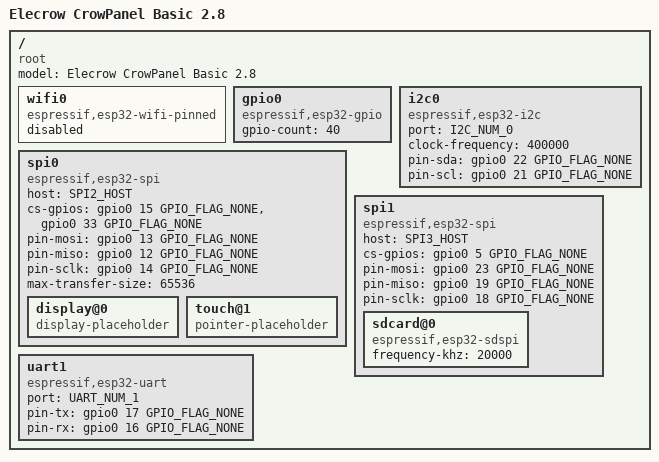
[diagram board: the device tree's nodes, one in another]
/dts-v1/;

#include <tactility/bindings/root.h>
#include <tactility/bindings/esp32_wifi_pinned.h>
#include <tactility/bindings/esp32_gpio.h>
#include <tactility/bindings/esp32_i2c.h>
#include <tactility/bindings/esp32_spi.h>
#include <tactility/bindings/esp32_uart.h>
#include <tactility/bindings/esp32_sdspi.h>
#include <tactility/bindings/display_placeholder.h>
#include <tactility/bindings/pointer_placeholder.h>

/ {
	compatible = "root";
	model = "Elecrow CrowPanel Basic 2.8";

	wifi0 {
		compatible = "espressif,esp32-wifi-pinned";
		status = "disabled";
	};

	gpio0 {
		compatible = "espressif,esp32-gpio";
		gpio-count = <40>;
	};

	i2c0 {
		compatible = "espressif,esp32-i2c";
		port = <I2C_NUM_0>;
		clock-frequency = <400000>;
		pin-sda = <&gpio0 22 GPIO_FLAG_NONE>;
		pin-scl = <&gpio0 21 GPIO_FLAG_NONE>;
	};

	spi0 {
		compatible = "espressif,esp32-spi";
		host = <SPI2_HOST>;
		cs-gpios = <&gpio0 15 GPIO_FLAG_NONE>, // Display
		            <&gpio0 33 GPIO_FLAG_NONE>; // Touch
		pin-mosi = <&gpio0 13 GPIO_FLAG_NONE>;
		pin-miso = <&gpio0 12 GPIO_FLAG_NONE>;
		pin-sclk = <&gpio0 14 GPIO_FLAG_NONE>;
		max-transfer-size = <65536>;
	
		display@0 {
			compatible = "display-placeholder";
		};

		touch@1 {
			compatible = "pointer-placeholder";
		};
	};

	spi1 {
		compatible = "espressif,esp32-spi";
		host = <SPI3_HOST>;
		cs-gpios = <&gpio0 5 GPIO_FLAG_NONE>;
		pin-mosi = <&gpio0 23 GPIO_FLAG_NONE>;
		pin-miso = <&gpio0 19 GPIO_FLAG_NONE>;
		pin-sclk = <&gpio0 18 GPIO_FLAG_NONE>;
	
		sdcard@0 {
			compatible = "espressif,esp32-sdspi";
			frequency-khz = <20000>;
		};
	};

	uart1 {
		compatible = "espressif,esp32-uart";
		port = <UART_NUM_1>;
		pin-tx = <&gpio0 17 GPIO_FLAG_NONE>;
		pin-rx = <&gpio0 16 GPIO_FLAG_NONE>;
	};
};
